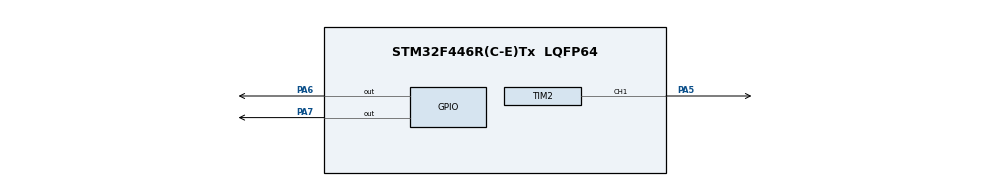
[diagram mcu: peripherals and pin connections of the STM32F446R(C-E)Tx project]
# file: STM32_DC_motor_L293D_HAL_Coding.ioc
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Mcu.Family=STM32F4
Mcu.Name=STM32F446R(C-E)Tx
Mcu.Package=LQFP64
NVIC.PriorityGroup=NVIC_PRIORITYGROUP_4
PA5.GPIO_Speed=GPIO_SPEED_FREQ_HIGH
PA5.Signal=S_TIM2_CH1_ETR
PA6.GPIO_Speed=GPIO_SPEED_FREQ_HIGH
PA6.Signal=GPIO_Output
PA7.GPIO_Speed=GPIO_SPEED_FREQ_HIGH
PA7.Signal=GPIO_Output
ProjectManager.HeapSize=0x200
ProjectManager.StackSize=0x400
ProjectManager.TargetToolchain=STM32CubeIDE
RCC.CortexFreq_Value=16000000
RCC.USBFreq_Value=96000000
RCC.VCOOutputFreq_Value=192000000
SH.S_TIM2_CH1_ETR.0=TIM2_CH1,PWM Generation1 CH1
TIM2.AutoReloadPreload=TIM_AUTORELOAD_PRELOAD_ENABLE
TIM2.Channel-PWM\ Generation1\ CH1=TIM_CHANNEL_1
TIM2.Period=1000
TIM2.Prescaler=84
board=custom

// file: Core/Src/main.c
/* USER CODE BEGIN Header */
/**
  ******************************************************************************
  * @file           : main.c
  * @brief          : Main program body
  ******************************************************************************
  * @attention
  *
  * Copyright (c) 2026 STMicroelectronics.
  * All rights reserved.
  *
  * This software is licensed under terms that can be found in the LICENSE file
  * in the root directory of this software component.
  * If no LICENSE file comes with this software, it is provided AS-IS.
  *
  ******************************************************************************
  */
/* USER CODE END Header */
#include "main.h"
#include "tim.h"
#include "gpio.h"

/* USER CODE BEGIN PD */

/* ===== PIN DEFINITIONS ===== */
#define IN1_PORT GPIOA
#define IN1_PIN  GPIO_PIN_6   // D12

#define IN2_PORT GPIOA
#define IN2_PIN  GPIO_PIN_7   // D11

#define EN_PWM_CHANNEL TIM_CHANNEL_1  // PA5 - D13

/* USER CODE END PD */

void SystemClock_Config(void);
/* USER CODE BEGIN PFP */
void motor_forward(void);
void motor_reverse(void);
void motor_stop(void);
void speed_up(void);
void speed_down(void);

/* USER CODE END PFP */

int main(void)
{

  /* MCU Configuration--------------------------------------------------------*/

  /* Reset of all peripherals, Initializes the Flash interface and the Systick. */
  HAL_Init();

  /* Configure the system clock */
  SystemClock_Config();

  /* Initialize all configured peripherals */
  MX_GPIO_Init();
  MX_TIM2_Init();
  /* USER CODE BEGIN 2 */
  HAL_TIM_PWM_Start(&htim2, EN_PWM_CHANNEL);
  /* USER CODE END 2 */

  /* Infinite loop */
  while (1)
  {

    /* USER CODE BEGIN 3 */
	  // ---- FORWARD ----
	      motor_forward();
	      speed_up();
	      speed_down();
	      motor_stop();
	      HAL_Delay(1000);

	      // ---- REVERSE ----
	      motor_reverse();
	      speed_up();
	      speed_down();
	      motor_stop();
	      HAL_Delay(1000);
  }
  /* USER CODE END 3 */
}

void SystemClock_Config(void)
{
  RCC_OscInitTypeDef RCC_OscInitStruct = {0};
  RCC_ClkInitTypeDef RCC_ClkInitStruct = {0};

  /** Configure the main internal regulator output voltage
  */
  __HAL_RCC_PWR_CLK_ENABLE();
  __HAL_PWR_VOLTAGESCALING_CONFIG(PWR_REGULATOR_VOLTAGE_SCALE3);

  /** Initializes the RCC Oscillators according to the specified parameters
  * in the RCC_OscInitTypeDef structure.
  */
  RCC_OscInitStruct.OscillatorType = RCC_OSCILLATORTYPE_HSI;
  RCC_OscInitStruct.HSIState = RCC_HSI_ON;
  RCC_OscInitStruct.HSICalibrationValue = RCC_HSICALIBRATION_DEFAULT;
  RCC_OscInitStruct.PLL.PLLState = RCC_PLL_NONE;
  if (HAL_RCC_OscConfig(&RCC_OscInitStruct) != HAL_OK)
  {
    Error_Handler();
  }

  /** Initializes the CPU, AHB and APB buses clocks
  */
  RCC_ClkInitStruct.ClockType = RCC_CLOCKTYPE_HCLK|RCC_CLOCKTYPE_SYSCLK
                              |RCC_CLOCKTYPE_PCLK1|RCC_CLOCKTYPE_PCLK2;
  RCC_ClkInitStruct.SYSCLKSource = RCC_SYSCLKSOURCE_HSI;
  RCC_ClkInitStruct.AHBCLKDivider = RCC_SYSCLK_DIV1;
  RCC_ClkInitStruct.APB1CLKDivider = RCC_HCLK_DIV1;
  RCC_ClkInitStruct.APB2CLKDivider = RCC_HCLK_DIV1;

  if (HAL_RCC_ClockConfig(&RCC_ClkInitStruct, FLASH_LATENCY_0) != HAL_OK)
  {
    Error_Handler();
  }
}

/* USER CODE BEGIN 4 */
void motor_forward(void)
{
  HAL_GPIO_WritePin(IN1_PORT, IN1_PIN, GPIO_PIN_SET);
  HAL_GPIO_WritePin(IN2_PORT, IN2_PIN, GPIO_PIN_RESET);
}

void motor_reverse(void)
{
  HAL_GPIO_WritePin(IN1_PORT, IN1_PIN, GPIO_PIN_RESET);
  HAL_GPIO_WritePin(IN2_PORT, IN2_PIN, GPIO_PIN_SET);
}

void motor_stop(void)
{
  __HAL_TIM_SET_COMPARE(&htim2, EN_PWM_CHANNEL, 0);
  HAL_GPIO_WritePin(IN1_PORT, IN1_PIN, GPIO_PIN_RESET);
  HAL_GPIO_WritePin(IN2_PORT, IN2_PIN, GPIO_PIN_RESET);
}

/* ===== SPEED CONTROL ===== */
void speed_up(void)
{
  for (uint16_t duty = 0; duty <= 1000; duty += 50)
  {
    __HAL_TIM_SET_COMPARE(&htim2, EN_PWM_CHANNEL, duty);
    HAL_Delay(50);
  }
}

void speed_down(void)
{
  for (int duty = 1000; duty >= 0; duty -= 50)
  {
    __HAL_TIM_SET_COMPARE(&htim2, EN_PWM_CHANNEL, duty);
    HAL_Delay(50);
  }
}
/* USER CODE END 4 */

void Error_Handler(void)
{
  __disable_irq();
  while (1)
  {
  }
}
